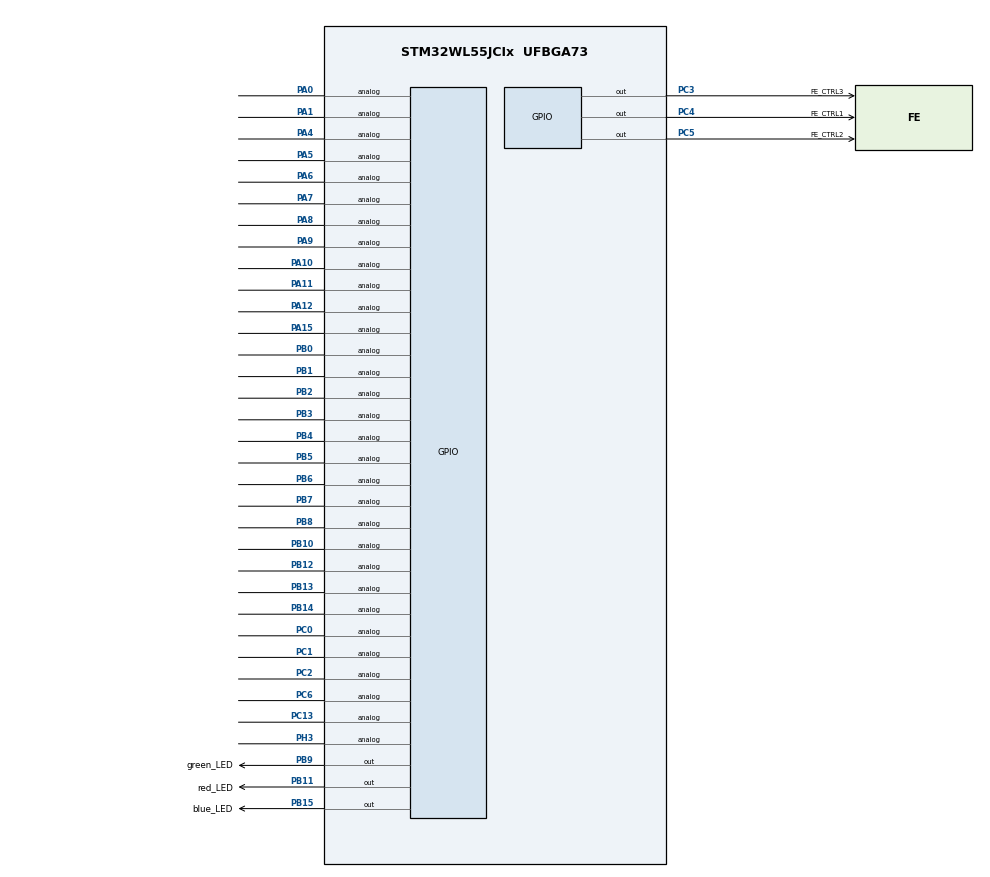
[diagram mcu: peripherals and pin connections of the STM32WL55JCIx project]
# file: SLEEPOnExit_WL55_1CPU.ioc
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Mcu.Family=STM32WL
Mcu.Name=STM32WL55JCIx
Mcu.Package=UFBGA73
NVIC.PriorityGroup=NVIC_PRIORITYGROUP_4
NVIC.TIM16_IRQn=true\:0\:0\:false\:false\:true\:true\:true\:true
PA0.Signal=GPIO_Analog
PA1.Signal=GPIO_Analog
PA10.Signal=GPIO_Analog
PA11.Signal=GPIO_Analog
PA12.Signal=GPIO_Analog
PA13.Mode=Serial_Wire
PA13.Signal=DEBUG_JTMS-SWDIO
PA14.Mode=Serial_Wire
PA14.Signal=DEBUG_JTCK-SWCLK
PA15.Signal=GPIO_Analog
PA2.GPIO_Label=T_VCP_RX
PA2.Signal=USART2_TX
PA3.GPIO_Label=T_VCP_RX
PA3.Signal=USART2_RX
PA4.Signal=GPIO_Analog
PA5.Signal=GPIO_Analog
PA6.Signal=GPIO_Analog
PA7.Signal=GPIO_Analog
PA8.Signal=GPIO_Analog
PA9.Signal=GPIO_Analog
PB0-VDD_TCXO.Signal=GPIO_Analog
PB1.Signal=GPIO_Analog
PB10.Signal=GPIO_Analog
PB11.GPIO_Label=red_LED
PB11.Signal=GPIO_Output
PB12.Signal=GPIO_Analog
PB13.Signal=GPIO_Analog
PB14.Signal=GPIO_Analog
PB15.GPIO_Label=blue_LED
PB15.Signal=GPIO_Output
PB2.Signal=GPIO_Analog
PB3.Signal=GPIO_Analog
PB4.Signal=GPIO_Analog
PB5.Signal=GPIO_Analog
PB6.Signal=GPIO_Analog
PB7.Signal=GPIO_Analog
PB8.Signal=GPIO_Analog
PB9.GPIO_Label=green_LED
PB9.Signal=GPIO_Output
PC0.Signal=GPIO_Analog
PC1.Signal=GPIO_Analog
PC13.Signal=GPIO_Analog
PC14-OSC32_IN.GPIO_Label=RCC_OSC32_IN
PC14-OSC32_IN.Signal=RCC_OSC32_IN
PC15-OSC32_OUT.GPIO_Label=RCC_OSC32_OUT
PC15-OSC32_OUT.Signal=RCC_OSC32_OUT
PC2.Signal=GPIO_Analog
PC3.GPIO_Label=FE_CTRL3
PC3.GPIO_Speed=GPIO_SPEED_FREQ_VERY_HIGH
PC3.Signal=GPIO_Output
PC4.GPIO_Label=FE_CTRL1
PC4.GPIO_Speed=GPIO_SPEED_FREQ_VERY_HIGH
PC4.Signal=GPIO_Output
PC5.GPIO_Label=FE_CTRL2
PC5.GPIO_Speed=GPIO_SPEED_FREQ_VERY_HIGH
PC5.Signal=GPIO_Output
PC6.Signal=GPIO_Analog
PH3-BOOT0.Signal=GPIO_Analog
ProjectManager.HeapSize=0x200
ProjectManager.StackSize=0x400
ProjectManager.TargetToolchain=STM32CubeIDE
RCC.AHBCLKDivider=RCC_SYSCLK_DIV4
RCC.AHBFreq_Value=12000000
RCC.APB1Freq_Value=12000000
RCC.APB1TimFreq_Value=12000000
RCC.APB2CLKDivider=RCC_HCLK_DIV8
RCC.APB2Freq_Value=1500000
RCC.APB2TimFreq_Value=3000000
RCC.APB3Freq_Value=48000000
RCC.CortexFreq_Value=12000000
RCC.HCLKFreq_Value=12000000
RCC.HSE_VALUE=32000000
RCC.HSI_VALUE=16000000
RCC.LSE_VALUE=32768
RCC.PLLN=24
RCC.SYSCLKFreq_VALUE=48000000
RCC.SYSCLKSource=RCC_SYSCLKSOURCE_PLLCLK
RCC.VCOOutputFreq_Value=96000000
TIM16.Period=10000 - 1
TIM16.Prescaler=300 - 1
VP_TIM16_VS_ClockSourceINT.Mode=Enable_Timer
board=NUCLEO-WL55JC1

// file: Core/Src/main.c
/* USER CODE BEGIN Header */
/**
  ******************************************************************************
  * @file           : main.c
  * @brief          : Main program body
  ******************************************************************************
  * @attention
  *
  * Copyright (c) 2025 STMicroelectronics.
  * All rights reserved.
  *
  * This software is licensed under terms that can be found in the LICENSE file
  * in the root directory of this software component.
  * If no LICENSE file comes with this software, it is provided AS-IS.
  *
  ******************************************************************************
  */
/* USER CODE END Header */
#include "main.h"

TIM_HandleTypeDef htim16;

void SystemClock_Config(void);
static void MX_GPIO_Init(void);
static void MX_TIM16_Init(void);

/* USER CODE BEGIN 0 */
void HAL_TIM_PeriodElapsedCallback(TIM_HandleTypeDef *htim){
	HAL_ResumeTick(); // MCU wakes up from sleep mode

	// Check which version of the timer triggered this callback and toggle LED
	if (htim == &htim16){
		HAL_GPIO_TogglePin(GPIOB, GPIO_PIN_15);
	}

	HAL_SuspendTick();

  /* ####----####----####----####----####
	  * MCU will sleep when exiting this ISR
	  * ####----####----####----####----####
	  */
}
/* USER CODE END 0 */

int main(void)
{

  /* MCU Configuration--------------------------------------------------------*/

  /* Reset of all peripherals, Initializes the Flash interface and the Systick. */
  HAL_Init();

  /* Configure the system clock */
  SystemClock_Config();

  /* Initialize all configured peripherals */
  MX_GPIO_Init();
  MX_TIM16_Init();
  /* USER CODE BEGIN 2 */
  HAL_TIM_Base_Start_IT(&htim16);
  HAL_PWR_EnableSleepOnExit();
  HAL_GPIO_WritePin(GPIOB, GPIO_PIN_15, 1);
  /* USER CODE END 2 */

  /* Infinite loop */
  while (1)
  {

  }
}

void SystemClock_Config(void)
{
  RCC_OscInitTypeDef RCC_OscInitStruct = {0};
  RCC_ClkInitTypeDef RCC_ClkInitStruct = {0};

  /** Configure the main internal regulator output voltage
  */
  __HAL_PWR_VOLTAGESCALING_CONFIG(PWR_REGULATOR_VOLTAGE_SCALE1);

  /** Initializes the CPU, AHB and APB buses clocks
  */
  RCC_OscInitStruct.OscillatorType = RCC_OSCILLATORTYPE_MSI;
  RCC_OscInitStruct.MSIState = RCC_MSI_ON;
  RCC_OscInitStruct.MSICalibrationValue = RCC_MSICALIBRATION_DEFAULT;
  RCC_OscInitStruct.MSIClockRange = RCC_MSIRANGE_6;
  RCC_OscInitStruct.PLL.PLLState = RCC_PLL_ON;
  RCC_OscInitStruct.PLL.PLLSource = RCC_PLLSOURCE_MSI;
  RCC_OscInitStruct.PLL.PLLM = RCC_PLLM_DIV1;
  RCC_OscInitStruct.PLL.PLLN = 24;
  RCC_OscInitStruct.PLL.PLLP = RCC_PLLP_DIV2;
  RCC_OscInitStruct.PLL.PLLR = RCC_PLLR_DIV2;
  RCC_OscInitStruct.PLL.PLLQ = RCC_PLLQ_DIV2;
  if (HAL_RCC_OscConfig(&RCC_OscInitStruct) != HAL_OK)
  {
    Error_Handler();
  }

  /** Configure the SYSCLKSource, HCLK, PCLK1 and PCLK2 clocks dividers
  */
  RCC_ClkInitStruct.ClockType = RCC_CLOCKTYPE_HCLK3|RCC_CLOCKTYPE_HCLK
                              |RCC_CLOCKTYPE_SYSCLK|RCC_CLOCKTYPE_PCLK1
                              |RCC_CLOCKTYPE_PCLK2;
  RCC_ClkInitStruct.SYSCLKSource = RCC_SYSCLKSOURCE_PLLCLK;
  RCC_ClkInitStruct.AHBCLKDivider = RCC_SYSCLK_DIV4;
  RCC_ClkInitStruct.APB1CLKDivider = RCC_HCLK_DIV1;
  RCC_ClkInitStruct.APB2CLKDivider = RCC_HCLK_DIV8;
  RCC_ClkInitStruct.AHBCLK3Divider = RCC_SYSCLK_DIV1;

  if (HAL_RCC_ClockConfig(&RCC_ClkInitStruct, FLASH_LATENCY_2) != HAL_OK)
  {
    Error_Handler();
  }
}

static void MX_TIM16_Init(void)
{

  htim16.Instance = TIM16;
  htim16.Init.Prescaler = 300 - 1;
  htim16.Init.CounterMode = TIM_COUNTERMODE_UP;
  htim16.Init.Period = 10000 - 1;
  htim16.Init.ClockDivision = TIM_CLOCKDIVISION_DIV1;
  htim16.Init.RepetitionCounter = 0;
  htim16.Init.AutoReloadPreload = TIM_AUTORELOAD_PRELOAD_DISABLE;
  if (HAL_TIM_Base_Init(&htim16) != HAL_OK)
  {
    Error_Handler();
  }

}

static void MX_GPIO_Init(void)
{
  GPIO_InitTypeDef GPIO_InitStruct = {0};

  /* GPIO Ports Clock Enable */
  __HAL_RCC_GPIOA_CLK_ENABLE();
  __HAL_RCC_GPIOB_CLK_ENABLE();
  __HAL_RCC_GPIOC_CLK_ENABLE();
  __HAL_RCC_GPIOH_CLK_ENABLE();

  /*Configure GPIO pin Output Level */
  HAL_GPIO_WritePin(GPIOB, blue_LED_Pin|green_LED_Pin|red_LED_Pin, GPIO_PIN_RESET);

  /*Configure GPIO pin Output Level */
  HAL_GPIO_WritePin(GPIOC, FE_CTRL3_Pin|FE_CTRL2_Pin|FE_CTRL1_Pin, GPIO_PIN_RESET);

  /*Configure GPIO pins : PA12 PA15 PA11 PA10
                           PA0 PA9 PA6 PA1
                           PA7 PA4 PA5 PA8 */
  GPIO_InitStruct.Pin = GPIO_PIN_12|GPIO_PIN_15|GPIO_PIN_11|GPIO_PIN_10
                          |GPIO_PIN_0|GPIO_PIN_9|GPIO_PIN_6|GPIO_PIN_1
                          |GPIO_PIN_7|GPIO_PIN_4|GPIO_PIN_5|GPIO_PIN_8;
  GPIO_InitStruct.Mode = GPIO_MODE_ANALOG;
  GPIO_InitStruct.Pull = GPIO_NOPULL;
  HAL_GPIO_Init(GPIOA, &GPIO_InitStruct);

  /*Configure GPIO pins : blue_LED_Pin green_LED_Pin red_LED_Pin */
  GPIO_InitStruct.Pin = blue_LED_Pin|green_LED_Pin|red_LED_Pin;
  GPIO_InitStruct.Mode = GPIO_MODE_OUTPUT_PP;
  GPIO_InitStruct.Pull = GPIO_NOPULL;
  GPIO_InitStruct.Speed = GPIO_SPEED_FREQ_LOW;
  HAL_GPIO_Init(GPIOB, &GPIO_InitStruct);

  /*Configure GPIO pins : PB3 PB4 PB7 PB14
                           PB5 PB8 PB13 PB2
                           PB6 PB12 PB1 PB0
                           PB10 */
  GPIO_InitStruct.Pin = GPIO_PIN_3|GPIO_PIN_4|GPIO_PIN_7|GPIO_PIN_14
                          |GPIO_PIN_5|GPIO_PIN_8|GPIO_PIN_13|GPIO_PIN_2
                          |GPIO_PIN_6|GPIO_PIN_12|GPIO_PIN_1|GPIO_PIN_0
                          |GPIO_PIN_10;
  GPIO_InitStruct.Mode = GPIO_MODE_ANALOG;
  GPIO_InitStruct.Pull = GPIO_NOPULL;
  HAL_GPIO_Init(GPIOB, &GPIO_InitStruct);

  /*Configure GPIO pins : PC13 PC2 PC1 PC0
                           PC6 */
  GPIO_InitStruct.Pin = GPIO_PIN_13|GPIO_PIN_2|GPIO_PIN_1|GPIO_PIN_0
                          |GPIO_PIN_6;
  GPIO_InitStruct.Mode = GPIO_MODE_ANALOG;
  GPIO_InitStruct.Pull = GPIO_NOPULL;
  HAL_GPIO_Init(GPIOC, &GPIO_InitStruct);

  /*Configure GPIO pins : FE_CTRL3_Pin FE_CTRL2_Pin FE_CTRL1_Pin */
  GPIO_InitStruct.Pin = FE_CTRL3_Pin|FE_CTRL2_Pin|FE_CTRL1_Pin;
  GPIO_InitStruct.Mode = GPIO_MODE_OUTPUT_PP;
  GPIO_InitStruct.Pull = GPIO_NOPULL;
  GPIO_InitStruct.Speed = GPIO_SPEED_FREQ_VERY_HIGH;
  HAL_GPIO_Init(GPIOC, &GPIO_InitStruct);

  /*Configure GPIO pins : T_VCP_RX_Pin T_VCP_RXA2_Pin */
  GPIO_InitStruct.Pin = T_VCP_RX_Pin|T_VCP_RXA2_Pin;
  GPIO_InitStruct.Mode = GPIO_MODE_AF_PP;
  GPIO_InitStruct.Pull = GPIO_NOPULL;
  GPIO_InitStruct.Speed = GPIO_SPEED_FREQ_LOW;
  GPIO_InitStruct.Alternate = GPIO_AF7_USART2;
  HAL_GPIO_Init(GPIOA, &GPIO_InitStruct);

  /*Configure GPIO pin : PH3 */
  GPIO_InitStruct.Pin = GPIO_PIN_3;
  GPIO_InitStruct.Mode = GPIO_MODE_ANALOG;
  GPIO_InitStruct.Pull = GPIO_NOPULL;
  HAL_GPIO_Init(GPIOH, &GPIO_InitStruct);

}

void Error_Handler(void)
{
  __disable_irq();
  while (1)
  {
  }
}
